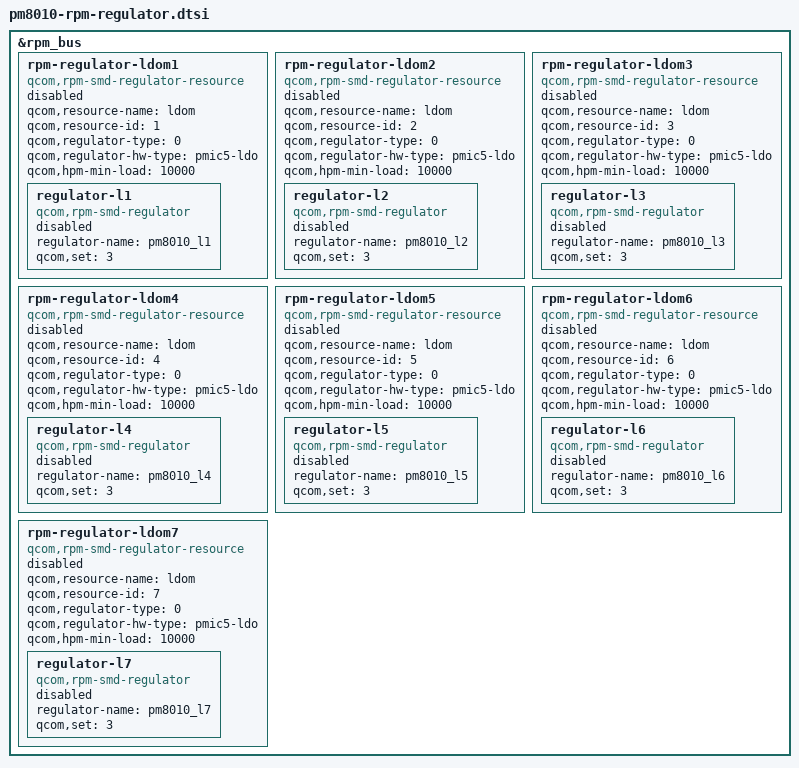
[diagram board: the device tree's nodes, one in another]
&rpm_bus {
	rpm-regulator-ldom1 {
		compatible = "qcom,rpm-smd-regulator-resource";
		qcom,resource-name = "ldom";
		qcom,resource-id = <1>;
		qcom,regulator-type = <0>;
		qcom,regulator-hw-type = "pmic5-ldo";
		qcom,hpm-min-load = <10000>;
		status = "disabled";

		regulator-l1 {
			compatible = "qcom,rpm-smd-regulator";
			regulator-name = "pm8010_l1";
			qcom,set = <3>;
			status = "disabled";
		};
	};

	rpm-regulator-ldom2 {
		compatible = "qcom,rpm-smd-regulator-resource";
		qcom,resource-name = "ldom";
		qcom,resource-id = <2>;
		qcom,regulator-type = <0>;
		qcom,regulator-hw-type = "pmic5-ldo";
		qcom,hpm-min-load = <10000>;
		status = "disabled";

		regulator-l2 {
			compatible = "qcom,rpm-smd-regulator";
			regulator-name = "pm8010_l2";
			qcom,set = <3>;
			status = "disabled";
		};
	};

	rpm-regulator-ldom3 {
		compatible = "qcom,rpm-smd-regulator-resource";
		qcom,resource-name = "ldom";
		qcom,resource-id = <3>;
		qcom,regulator-type = <0>;
		qcom,regulator-hw-type = "pmic5-ldo";
		qcom,hpm-min-load = <10000>;
		status = "disabled";

		regulator-l3 {
			compatible = "qcom,rpm-smd-regulator";
			regulator-name = "pm8010_l3";
			qcom,set = <3>;
			status = "disabled";
		};
	};

	rpm-regulator-ldom4 {
		compatible = "qcom,rpm-smd-regulator-resource";
		qcom,resource-name = "ldom";
		qcom,resource-id = <4>;
		qcom,regulator-type = <0>;
		qcom,regulator-hw-type = "pmic5-ldo";
		qcom,hpm-min-load = <10000>;
		status = "disabled";

		regulator-l4 {
			compatible = "qcom,rpm-smd-regulator";
			regulator-name = "pm8010_l4";
			qcom,set = <3>;
			status = "disabled";
		};
	};

	rpm-regulator-ldom5 {
		compatible = "qcom,rpm-smd-regulator-resource";
		qcom,resource-name = "ldom";
		qcom,resource-id = <5>;
		qcom,regulator-type = <0>;
		qcom,regulator-hw-type = "pmic5-ldo";
		qcom,hpm-min-load = <10000>;
		status = "disabled";

		regulator-l5 {
			compatible = "qcom,rpm-smd-regulator";
			regulator-name = "pm8010_l5";
			qcom,set = <3>;
			status = "disabled";
		};
	};

	rpm-regulator-ldom6 {
		compatible = "qcom,rpm-smd-regulator-resource";
		qcom,resource-name = "ldom";
		qcom,resource-id = <6>;
		qcom,regulator-type = <0>;
		qcom,regulator-hw-type = "pmic5-ldo";
		qcom,hpm-min-load = <10000>;
		status = "disabled";

		regulator-l6 {
			compatible = "qcom,rpm-smd-regulator";
			regulator-name = "pm8010_l6";
			qcom,set = <3>;
			status = "disabled";
		};
	};

	rpm-regulator-ldom7 {
		compatible = "qcom,rpm-smd-regulator-resource";
		qcom,resource-name = "ldom";
		qcom,resource-id = <7>;
		qcom,regulator-type = <0>;
		qcom,regulator-hw-type = "pmic5-ldo";
		qcom,hpm-min-load = <10000>;
		status = "disabled";

		regulator-l7 {
			compatible = "qcom,rpm-smd-regulator";
			regulator-name = "pm8010_l7";
			qcom,set = <3>;
			status = "disabled";
		};
	};
};
